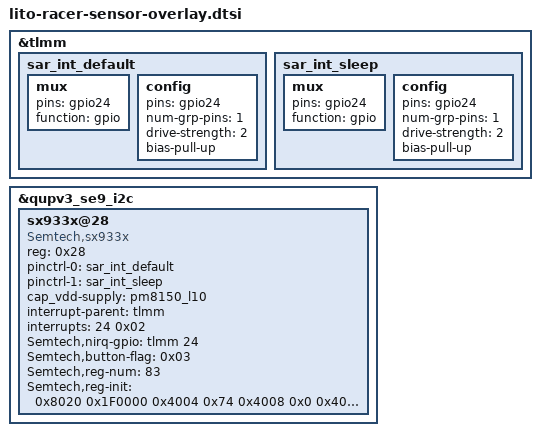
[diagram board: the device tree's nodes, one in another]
/* Copyright (c) 2019, The Linux Foundation. All rights reserved.
 *
 * This program is free software; you can redistribute it and/or modify
 * it under the terms of the GNU General Public License version 2 and
 * only version 2 as published by the Free Software Foundation.
 *
 * This program is distributed in the hope that it will be useful,
 * but WITHOUT ANY WARRANTY; without even the implied warranty of
 * MERCHANTABILITY or FITNESS FOR A PARTICULAR PURPOSE.  See the
 * GNU General Public License for more details.
 */

&tlmm {
	sar_int_default: sar_int_default {
			mux {
				pins = "gpio24";
				function =  "gpio";
			};
			config {
				pins = "gpio24";
				num-grp-pins = <1>;
				drive-strength = <2>;
				bias-pull-up;
			};
	};

	sar_int_sleep: sar_int_sleep {
			mux {
				pins = "gpio24";
				function =  "gpio";
			};
			config {
				pins = "gpio24";
				num-grp-pins = <1>;
				drive-strength = <2>;
				bias-pull-up;
			};
	};
};


&qupv3_se9_i2c {
	status = "ok";
	sx933x@28 { /* SAR sensor */
		compatible = "Semtech,sx933x";
		reg = <0x28>;
		pinctrl-names = "default","sleep";
		pinctrl-0 = <&sar_int_default>;
		pinctrl-1 = <&sar_int_sleep>;
		cap_vdd-supply = <&pm8150_l10>;
		interrupt-parent = <&tlmm>;
		interrupts = <24 0x02>;
		interrupt-names = "sx933x_irq";
		Semtech,nirq-gpio= <&tlmm 24 0x02>;
		Semtech,button-flag = <0x03>;
		Semtech,reg-num = <83>;
		Semtech,reg-init =<
		0x8020 0x1F0000
		0x4004 0x74
		0x4008 0x0
		0x4054 0x400
		0x42c0 0x8000000
		0x42c4 0x3f
		0x800c 0x0
		0x8010 0x0
		0x8014 0x0
		0x8018 0x0
		0x801c 0x14
		0x8024 0x1000049E
		0x8028 0x3FFE8257
		0x802c 0x20000ABE
		0x8030 0x3ff7825b
		0x8034 0x0
		0x8038 0x0
		0x803c 0x20000ABE
		0x8040 0x3dff82cb
		0x8044 0x1000049E
		0x8048 0x2fff82d4
		0x804c 0x0
		0x8050 0x0
		0x8054 0x08282C15
		0x8058 0x20630018
		0x805C 0x46C47000
		0x8060 0x00000000
		0x8064 0x00540000
		0x8068 0x00000000
		0x806C 0x00390039
		0x8070 0x00020000
		0x8074 0x08283515
		0x8078 0x20630018
		0x807c 0x46C47000
		0x8080 0x0
		0x8084 0x00760000
		0x8088 0x0
		0x808c 0x23002300
		0x8090 0x10000
		0x8094 0x0
		0x8098 0x0
		0x809c 0x0
		0x80a0 0x0
		0x80a4 0x0
		0x80a8 0x0
		0x80ac 0x0
		0x80b0 0x00000
		0x80b4 0x00304319
		0x80b8 0x20630050
		0x80bc 0x50B05000
		0x80c0 0x0
		0x80c4 0x0
		0x80c8 0x0
		0x80cc 0x0
		0x80d0 0x0
		0x80d4 0x10483315
		0x80d8 0x20630030
		0x80dc 0x50B05000
		0x80e0 0x0
		0x80e4 0x0
		0x80e8 0x0
		0x80ec 0x0
		0x80f0 0x0
		0x80f4 0x0
		0x80f8 0x0
		0x80fc 0x0
		0x8100 0x0
		0x8104 0x0
		0x8108 0x0
		0x810c 0x0
		0x8110 0x0
		0x8124 0x400000B
		0x8128 0x400000C
		0x812c 0x0
		0x8130 0x0
		0x8134 0x0
		0x8138 0x0
		0x813c 0x0
		0x8140 0x0
		0x8144 0x0
		0x8148 0x0
		0x814c 0x0
		0x81a4 0x1c40008>;
		status = "ok";
	};
};
